# MCU_SEC_MMR0_CFG0 register map
Vendor: Texas Instruments
Peripheral module from a debugger description file (folder J7_AHP).
Registers are 32-bit, read-write, reset 0x0 unless marked. A register's access mark holds for its fields unless they carry their own. Offsets are as the file gives them; lines under a group give offsets from that group; [hi:lo] are bit positions; {n}, {i} and the like mark numbered series; 'fields as' and 'values as' point back to an identical list; <NAME> marks a mode.

## MCU_SEC_MMR0_CFG0
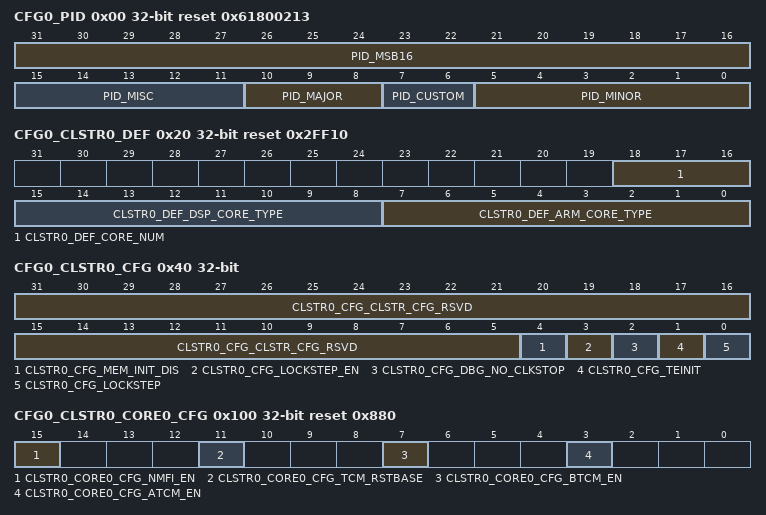
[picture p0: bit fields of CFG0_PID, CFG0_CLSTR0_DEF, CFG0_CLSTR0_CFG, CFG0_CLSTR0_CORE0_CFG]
0x00 CFG0_PID ro reset 0x61800213
  [31:16] PID_MSB16, [15:11] PID_MISC, [10:8] PID_MAJOR, [7:6] PID_CUSTOM, [5:0] PID_MINOR
0x20 CFG0_CLSTR0_DEF ro reset 0x2FF10
  [18:16] CLSTR0_DEF_CORE_NUM — Number of cores in cluster
  [15:8] CLSTR0_DEF_DSP_CORE_TYPE — DSP core type configuration
  [7:0] CLSTR0_DEF_ARM_CORE_TYPE — ARM core type configuration
0x40 CFG0_CLSTR0_CFG access per field
  [31:5] CLSTR0_CFG_CLSTR_CFG_RSVD rw — Reserved for future use. Write '0' to ensure compatibility with future devices.
  [4] CLSTR0_CFG_MEM_INIT_DIS rw — Disables SRAM initialization (TCM, etc) at reset,
  [3] CLSTR0_CFG_LOCKSTEP_EN ro — Lockstep enable. Indicates if R5 lockstep operation is supported on the device
  [2] CLSTR0_CFG_DBG_NO_CLKSTOP rw — CPU clockstop behavior
  [1] CLSTR0_CFG_TEINIT rw — Exception handling state at reset:
  [0] CLSTR0_CFG_LOCKSTEP rw — When set, Core0 and Core1 operate in lockstep mode. Can only be changed if lockstep operation is supported as indicated by CLSTR0_CFG_lockstep_en = 1. If CLSTR0_CFG_lockstep_en = 0, lockstep is not supported, this bit will be read only with a value of 0.
0x80 CFG0_CLSTR0_PMCTRL access not given
0x90 CFG0_CLSTR0_PMSTAT access not given
0x100 CFG0_CLSTR0_CORE0_CFG reset 0x880
  [15] CLSTR0_CORE0_CFG_NMFI_EN — Enable Core0 Non-Maskable Fast Interrupts
  [11] CLSTR0_CORE0_CFG_TCM_RSTBASE — Core0 A/BTCM Reset Base Address Indicator
  [7] CLSTR0_CORE0_CFG_BTCM_EN — Enable Core0 BTCM RAM at reset
  [3] CLSTR0_CORE0_CFG_ATCM_EN — Enable Core0 ATCM RAM at reset
0x110 CFG0_CLSTR0_CORE0_BOOTVECT_LO reset 0x41800000
  [31:7] CLSTR0_CORE0_BOOTVECT_LO_VECT_ADDR — Specifies the lower 25 bits of the 41-bit vector address corresponding to Vector Table address bits[31:7]. Note bits 6:0 of the Vector Table address are always 0.
0x114 CFG0_CLSTR0_CORE0_BOOTVECT_HI
  [15:0] CLSTR0_CORE0_BOOTVECT_HI_VECT_ADDR — Specifies the upper 16 bits of the 41-bit vector address corresponding to Vector Table address bits[47:32].
0x120 CFG0_CLSTR0_CORE0_PMCTRL
  [0] CLSTR0_CORE0_PMCTRL_CORE_HALT — Halt Core0
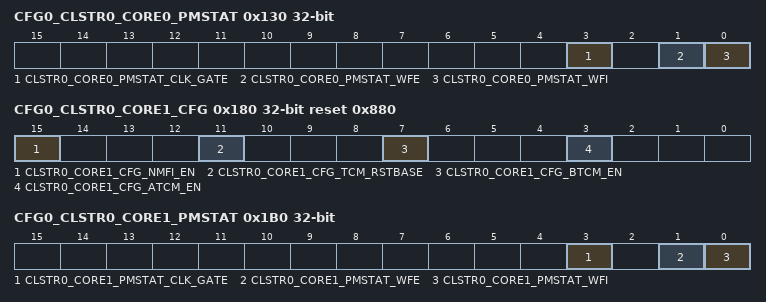
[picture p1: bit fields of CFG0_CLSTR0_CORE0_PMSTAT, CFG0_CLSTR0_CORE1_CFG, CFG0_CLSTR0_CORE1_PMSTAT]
0x130 CFG0_CLSTR0_CORE0_PMSTAT ro
  [3] CLSTR0_CORE0_PMSTAT_CLK_GATE — Core0 Clocked stopped due to WFI or WFE state
  [1] CLSTR0_CORE0_PMSTAT_WFE — Core0 WFE
  [0] CLSTR0_CORE0_PMSTAT_WFI — Core0 WFI
0x180 CFG0_CLSTR0_CORE1_CFG reset 0x880
  [15] CLSTR0_CORE1_CFG_NMFI_EN — Enable Core1 Non-Maskable Fast Interrupts
  [11] CLSTR0_CORE1_CFG_TCM_RSTBASE — Core1 A/BTCM Reset Base Address Indicator
  [7] CLSTR0_CORE1_CFG_BTCM_EN — Enable Core1 BTCM RAM at reset
  [3] CLSTR0_CORE1_CFG_ATCM_EN — Enable Core1 ATCM RAM at reset
0x190 CFG0_CLSTR0_CORE1_BOOTVECT_LO reset 0x41800000
  [31:7] CLSTR0_CORE1_BOOTVECT_LO_VECT_ADDR — Specifies the lower 25 bits of the 41-bit vector address corresponding to Vector Table address bits[31:7]. Note bits 6:0 of the Vector Table address are always 0.
0x194 CFG0_CLSTR0_CORE1_BOOTVECT_HI
  [15:0] CLSTR0_CORE1_BOOTVECT_HI_VECT_ADDR — Specifies the upper 16 bits of the 41-bit vector address corresponding to Vector Table address bits[47:32].
0x1A0 CFG0_CLSTR0_CORE1_PMCTRL
  [0] CLSTR0_CORE1_PMCTRL_CORE_HALT — Halt Core1
0x1B0 CFG0_CLSTR0_CORE1_PMSTAT ro
  [3] CLSTR0_CORE1_PMSTAT_CLK_GATE — Core1 Clocked stopped due to WFI or WFE state
  [1] CLSTR0_CORE1_PMSTAT_WFE — Core1 WFE
  [0] CLSTR0_CORE1_PMSTAT_WFI — Core1 WFI
